# CH32H417 register map
Vendor: WCH Ltd.; File version: 1.2
Registers are 32-bit, read-write, reset 0x0 unless marked. A register's access mark holds for its fields unless they carry their own. Offsets are from the block's base; [hi:lo] are bit positions.

## SPI1 — Serial peripheral interface
Base 0x40013000
Same registers: SPI4 0x40004000
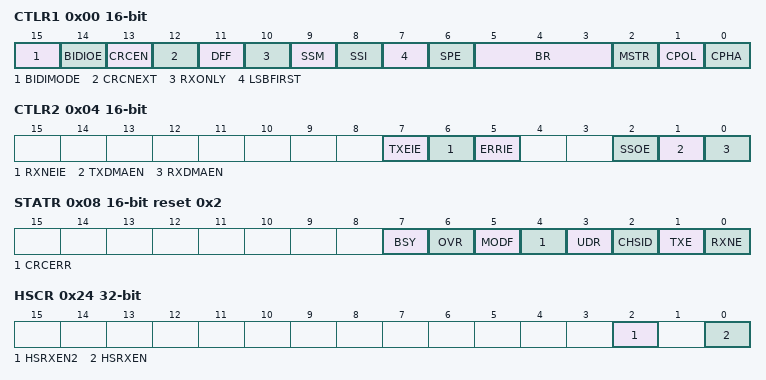
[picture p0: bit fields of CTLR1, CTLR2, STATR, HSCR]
0x00 CTLR1 16-bit — control register 1
  [15] BIDIMODE — Bidirectional data mode enable
  [14] BIDIOE — Output enable in bidirectional mode
  [13] CRCEN — Hardware CRC calculation enable
  [12] CRCNEXT — CRC transfer next
  [11] DFF — Data frame format
  [10] RXONLY — Receive only
  [9] SSM — Software slave management
  [8] SSI — Internal slave select
  [7] LSBFIRST — Frame format
  [6] SPE — SPI enable
  [5:3] BR — Baud rate control
  [2] MSTR — Master selection
  [1] CPOL — Clock polarity
  [0] CPHA — Clock phase
0x04 CTLR2 16-bit — control register 2
  [7] TXEIE — Tx buffer empty interrupt enable
  [6] RXNEIE — RX buffer not empty interrupt enable
  [5] ERRIE — Error interrupt enable
  [2] SSOE — SS output enable
  [1] TXDMAEN — Tx buffer DMA enable
  [0] RXDMAEN — Rx buffer DMA enable
0x08 STATR 16-bit access per field reset 0x2 — status register
  [7] BSY ro — Busy flag
  [6] OVR ro — Overrun flag
  [5] MODF ro — Mode fault
  [4] CRCERR rw — CRC error flag
  [3] UDR ro — Underrun flag
  [2] CHSID ro — Channel side
  [1] TXE ro — Transmit buffer empty
  [0] RXNE ro — Receive buffer not empty
0x0C DATAR 16-bit — data register
  [15:0] DR — Data register
0x10 CRCR 16-bit reset 0x7 — CRCR polynomial register
  [15:0] CRCPOLY — CRC polynomial register
0x14 RCRCR 16-bit ro — RX CRC register
  [15:0] RXCRC
0x18 TCRCR ro — TX CRC register
  [15:0] TXCRC
0x24 HSCR — high speed control register
  [2] HSRXEN2 — High speed mode 2 read enable
  [0] HSRXEN — High speed mode read enable

## SPI3 — Serial peripheral interface
Base 0x40003C00
Same registers: SPI2 0x40003800
Registers as SPI1; these are added or differ:
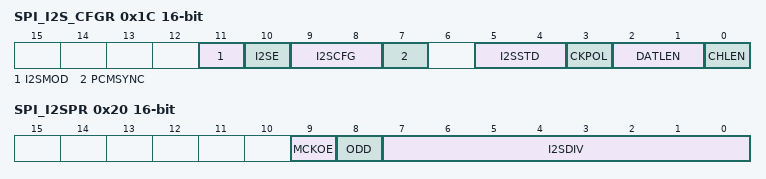
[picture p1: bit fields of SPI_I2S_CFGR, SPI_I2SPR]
0x1C SPI_I2S_CFGR 16-bit — SPI_I2S configure register
  [11] I2SMOD — I2S mode selection
  [10] I2SE — I2S Enable
  [9:8] I2SCFG — I2SCFG[1:0] bits (I2S configuration mode)
  [7] PCMSYNC — PCM frame synchronization
  [5:4] I2SSTD — I2SSTD[1:0] bits (I2S standard selection)
  [3] CKPOL — steady state clock polarity
  [2:1] DATLEN — DATLEN[1:0] bits (Data length to be transferred)
  [0] CHLEN — Channel length (number of bits per audio channel)
0x20 SPI_I2SPR 16-bit — I2S prescaler register
  [9] MCKOE — Master clock output enable
  [8] ODD — Odd factor for the prescaler
  [7:0] I2SDIV — I2S Linear prescaler

## USBPD — USBPD configuration
Base 0x40024400
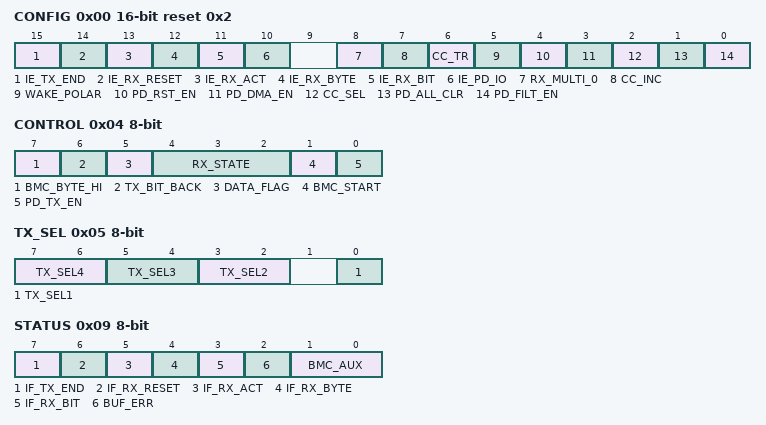
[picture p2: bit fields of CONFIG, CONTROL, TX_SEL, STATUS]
0x00 CONFIG 16-bit access per field reset 0x2 — PD interrupt enable register
  [15] IE_TX_END rw — transfer complete register
  [14] IE_RX_RESET rw — Receive complete rst register
  [13] IE_RX_ACT rw — Receive complete register
  [12] IE_RX_BYTE rw — Receive byte register
  [11] IE_RX_BIT rw — bit interrupt Enable
  [10] IE_PD_IO rw — IO Enable
  [8] RX_MULTI_0 ro — Continuously receive several bits of 0 indicator flag
  [7] CC_INC rw — CC bias current adjustment bit
  [6] CC_TR rw — TR conditioning of the CC LV waveform
  [5] WAKE_POLAR rw — wakeup polarity
  [4] PD_RST_EN rw — PD RST Enable
  [3] PD_DMA_EN rw — PD DMA Enable
  [2] CC_SEL rw — PD Commutation port
  [1] PD_ALL_CLR rw — PD ITClear
  [0] PD_FILT_EN rw — control PD pin input filter enable
0x02 BMC_CLK_CNT 16-bit — BMC sampling clock counter
  [8:0] BMC_CLK_CNT — R/T counter
0x04 CONTROL 8-bit access per field — PD Send and receive enable register
  [7] BMC_BYTE_HI ro — BMC_BYTE_HI value
  [6] TX_BIT_BACK ro — TX_BIT_BACK value
  [5] DATA_FLAG ro — DATA_FLAG value
  [4:2] RX_STATE rw — PD receive status identification
  [1] BMC_START rw — BMC_START value
  [0] PD_TX_EN rw — PD_TX_EN value
0x05 TX_SEL 8-bit — SOP port selection register
  [7:6] TX_SEL4 — TX_SEL4 value
  [5:4] TX_SEL3 — TX_SEL3 value
  [3:2] TX_SEL2 — TX_SEL2 value
  [0] TX_SEL1 — TX_SEL1 value
0x06 BMC_TX_SZ 16-bit — PD send length register
  [8:0] BMC_TX_SZ — BMC_TX_SZ value
0x08 DATA_BUF 8-bit ro — DMA cache data register
  [7:0] DATA_BUF — DATA_BUF value
0x09 STATUS 8-bit access per field — PD interrupt flag register
  [7] IF_TX_END rw — IF_TX_END value
  [6] IF_RX_RESET rw — IF_RX_RESET value
  [5] IF_RX_ACT rw — IF_RX_ACT value
  [4] IF_RX_BYTE rw — IF_RX_BYTE value
  [3] IF_RX_BIT rw — IF_RX_BIT value
  [2] BUF_ERR rw — BUF_ERR value
  [1:0] BMC_AUX ro — BMC_AUX value
0x0A BMC_BYTE_CNT 16-bit ro — Byte counter
  [8:0] BMC_BYTE_CNT — BMC_BYTE_CNT value
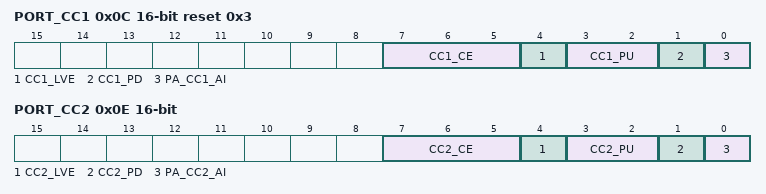
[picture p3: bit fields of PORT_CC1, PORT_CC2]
0x0C PORT_CC1 16-bit access per field reset 0x3 — CC1 port control register
  [7:5] CC1_CE rw — CC1_CE value
  [4] CC1_LVE rw — CC1_LVE value
  [3:2] CC1_PU rw — CC1_PU value
  [1] CC1_PD rw — port pull-down resistor enable
  [0] PA_CC1_AI ro — PA_CC1_AI value
0x0E PORT_CC2 16-bit — CC2 port control register
  [7:5] CC2_CE — CC2_CE value
  [4] CC2_LVE — CC2_LVE value
  [3:2] CC2_PU — CC2_PU value
  [1] CC2_PD — port pull-down resistor enable
  [0] PA_CC2_AI — PA_CC2_AI value
0x10 DMA — PD buffer start address register
  [20:0] USBPD_DMA_ADDR — USBPD_DMA_ADDR value
